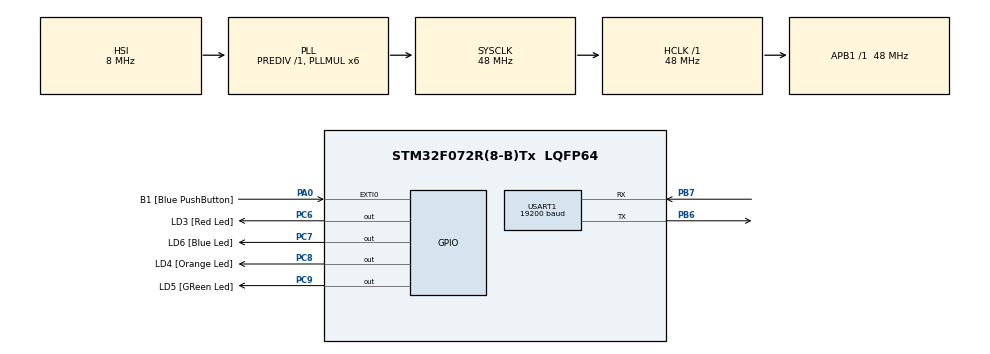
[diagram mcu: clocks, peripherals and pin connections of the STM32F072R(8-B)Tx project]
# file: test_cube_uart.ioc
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Mcu.Family=STM32F0
Mcu.Name=STM32F072R(8-B)Tx
Mcu.Package=LQFP64
NVIC.USART1_IRQn=true\:0\:0\:false\:false\:true\:true\:true
PA0.GPIO_Label=B1 [Blue PushButton]
PA0.GPIO_ModeDefaultEXTI=GPIO_MODE_EVT_RISING
PA0.Signal=GPXTI0
PA13.GPIO_Label=SWDIO
PA13.Mode=Serial_Wire
PA13.Signal=SYS_SWDIO
PA14.GPIO_Label=SWCLK
PA14.Mode=Serial_Wire
PA14.Signal=SYS_SWCLK
PB6.Mode=Asynchronous
PB6.Signal=USART1_TX
PB7.Mode=Asynchronous
PB7.Signal=USART1_RX
PC6.GPIO_Label=LD3 [Red Led]
PC6.Signal=GPIO_Output
PC7.GPIO_Label=LD6 [Blue Led]
PC7.Signal=GPIO_Output
PC8.GPIO_Label=LD4 [Orange Led]
PC8.Signal=GPIO_Output
PC9.GPIO_Label=LD5 [GReen Led]
PC9.Signal=GPIO_Output
ProjectManager.HeapSize=0x200
ProjectManager.StackSize=0x400
ProjectManager.TargetToolchain=SW4STM32
RCC.AHBFreq_Value=48000000
RCC.APB1Freq_Value=48000000
RCC.APB1TimFreq_Value=48000000
RCC.HCLKFreq_Value=48000000
RCC.PLLMUL=RCC_PLL_MUL6
RCC.SYSCLKFreq_VALUE=48000000
RCC.SYSCLKSource=RCC_SYSCLKSOURCE_PLLCLK
USART1.BaudRate=19200
USART1.Parity=PARITY_EVEN
USART1.VirtualMode-Asynchronous=VM_ASYNC
USART1.WordLength=WORDLENGTH_9B
board=32F072BDISCOVERY

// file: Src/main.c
/* USER CODE BEGIN Header */
/**
  ******************************************************************************
  * @file           : main.c
  * @brief          : Main program body
  ******************************************************************************
  * @attention
  *
  * <h2><center>&copy; Copyright (c) 2019 STMicroelectronics.
  * All rights reserved.</center></h2>
  *
  * This software component is licensed by ST under BSD 3-Clause license,
  * the "License"; You may not use this file except in compliance with the
  * License. You may obtain a copy of the License at:
  *                        opensource.org/licenses/BSD-3-Clause
  *
  ******************************************************************************
  */
/* USER CODE END Header */

#include "main.h"
#include "string.h"
#include "stm32f0xx_hal.h"

/* USER CODE BEGIN Includes */
#define BUFFERSIZE 	64

__IO ITStatus UartReady = RESET;
/* USER CODE END Includes */
uint8_t aTxBuffer[] = " ****UART_TwoBoards_ComIT****  ****UART_TwoBoards_ComIT****   ";
uint8_t aRxBuffer[BUFFERSIZE];
uint8_t byte;

UART_HandleTypeDef huart1;

void SystemClock_Config(void);
static void MX_GPIO_Init(void);
static void MX_USART1_UART_Init(void);

void debug_print(UART_HandleTypeDef *huart, char _out[])
{
	HAL_UART_Transmit(huart, (uint8_t *) _out, strlen(_out), 10);
}

void debug_println(UART_HandleTypeDef *huart, char _out[])
{
	HAL_UART_Transmit(huart, (uint8_t *) _out, strlen(_out), 10);
	char newline[2] = "\r\n";
	HAL_UART_Transmit(huart, (uint8_t *) newline, 2, 10);

}

/* This callback is called by the HAL_UART_IRQHandler when the given number of bytes are received */
void HAL_UART_RxCpltCallback(UART_HandleTypeDef *huart)
{
  if (huart->Instance == USART1)
  {
    /* Transmit one byte with 100 ms timeout */
    HAL_UART_Transmit(&huart1, &byte, 1, 100);

    /* Receive one byte in interrupt mode */
    HAL_UART_Receive_IT(&huart1, &byte, 1);
  }
}
int main(void)
{
  /* USER CODE BEGIN 1 */

	//char banner[20]="Hello World";
	//char buf[64];
  /* USER CODE END 1 */

  /* MCU Configuration--------------------------------------------------------*/

  /* Reset of all peripherals, Initializes the Flash interface and the Systick. */
  HAL_Init();

  /* Configure the system clock */
  SystemClock_Config();

  /* Initialize all configured peripherals */
  MX_GPIO_Init();
  MX_USART1_UART_Init();
  debug_println(&huart1,"print something...");
  HAL_Delay(1000);

  HAL_UART_Receive_IT(&huart1, &byte, 1);
  /* Infinite loop */
  while (1)
  {

	  //test only
	  /*
	  debug_println(&huart1,"print something...");
	  HAL_Delay(1000);
	  */
  }
}

void SystemClock_Config(void)
{
  RCC_OscInitTypeDef RCC_OscInitStruct = {0};
  RCC_ClkInitTypeDef RCC_ClkInitStruct = {0};
  RCC_PeriphCLKInitTypeDef PeriphClkInit = {0};

  /** Initializes the CPU, AHB and APB busses clocks
  */
  RCC_OscInitStruct.OscillatorType = RCC_OSCILLATORTYPE_HSI;
  RCC_OscInitStruct.HSIState = RCC_HSI_ON;
  RCC_OscInitStruct.HSICalibrationValue = RCC_HSICALIBRATION_DEFAULT;
  RCC_OscInitStruct.PLL.PLLState = RCC_PLL_ON;
  RCC_OscInitStruct.PLL.PLLSource = RCC_PLLSOURCE_HSI;
  RCC_OscInitStruct.PLL.PLLMUL = RCC_PLL_MUL6;
  RCC_OscInitStruct.PLL.PREDIV = RCC_PREDIV_DIV1;
  if (HAL_RCC_OscConfig(&RCC_OscInitStruct) != HAL_OK)
  {
    Error_Handler();
  }
  /** Initializes the CPU, AHB and APB busses clocks
  */
  RCC_ClkInitStruct.ClockType = RCC_CLOCKTYPE_HCLK|RCC_CLOCKTYPE_SYSCLK
                              |RCC_CLOCKTYPE_PCLK1;
  RCC_ClkInitStruct.SYSCLKSource = RCC_SYSCLKSOURCE_PLLCLK;
  RCC_ClkInitStruct.AHBCLKDivider = RCC_SYSCLK_DIV1;
  RCC_ClkInitStruct.APB1CLKDivider = RCC_HCLK_DIV1;

  if (HAL_RCC_ClockConfig(&RCC_ClkInitStruct, FLASH_LATENCY_1) != HAL_OK)
  {
    Error_Handler();
  }
  PeriphClkInit.PeriphClockSelection = RCC_PERIPHCLK_USART1;
  PeriphClkInit.Usart1ClockSelection = RCC_USART1CLKSOURCE_PCLK1;
  if (HAL_RCCEx_PeriphCLKConfig(&PeriphClkInit) != HAL_OK)
  {
    Error_Handler();
  }
}

static void MX_USART1_UART_Init(void)
{

  huart1.Instance = USART1;
  huart1.Init.BaudRate = 19200;
  huart1.Init.WordLength = UART_WORDLENGTH_9B;
  huart1.Init.StopBits = UART_STOPBITS_1;
  huart1.Init.Parity = UART_PARITY_EVEN;
  huart1.Init.Mode = UART_MODE_TX_RX;
  huart1.Init.HwFlowCtl = UART_HWCONTROL_NONE;
  huart1.Init.OverSampling = UART_OVERSAMPLING_16;
  huart1.Init.OneBitSampling = UART_ONE_BIT_SAMPLE_DISABLE;
  huart1.AdvancedInit.AdvFeatureInit = UART_ADVFEATURE_NO_INIT;
  if (HAL_UART_Init(&huart1) != HAL_OK)
  {
    Error_Handler();
  }

}

static void MX_GPIO_Init(void)
{
  GPIO_InitTypeDef GPIO_InitStruct = {0};

  /* GPIO Ports Clock Enable */
  __HAL_RCC_GPIOA_CLK_ENABLE();
  __HAL_RCC_GPIOC_CLK_ENABLE();
  __HAL_RCC_GPIOB_CLK_ENABLE();

  /*Configure GPIO pin Output Level */
  HAL_GPIO_WritePin(GPIOC, LD3_Pin|LD6_Pin|LD4_Pin|LD5_Pin, GPIO_PIN_RESET);

  /*Configure GPIO pin : B1_Pin */
  GPIO_InitStruct.Pin = B1_Pin;
  GPIO_InitStruct.Mode = GPIO_MODE_EVT_RISING;
  GPIO_InitStruct.Pull = GPIO_NOPULL;
  HAL_GPIO_Init(B1_GPIO_Port, &GPIO_InitStruct);

  /*Configure GPIO pins : LD3_Pin LD6_Pin LD4_Pin LD5_Pin */
  GPIO_InitStruct.Pin = LD3_Pin|LD6_Pin|LD4_Pin|LD5_Pin;
  GPIO_InitStruct.Mode = GPIO_MODE_OUTPUT_PP;
  GPIO_InitStruct.Pull = GPIO_NOPULL;
  GPIO_InitStruct.Speed = GPIO_SPEED_FREQ_LOW;
  HAL_GPIO_Init(GPIOC, &GPIO_InitStruct);

}

void Error_Handler(void)
{
}

/************************ (C) COPYRIGHT STMicroelectronics *****END OF FILE****/
